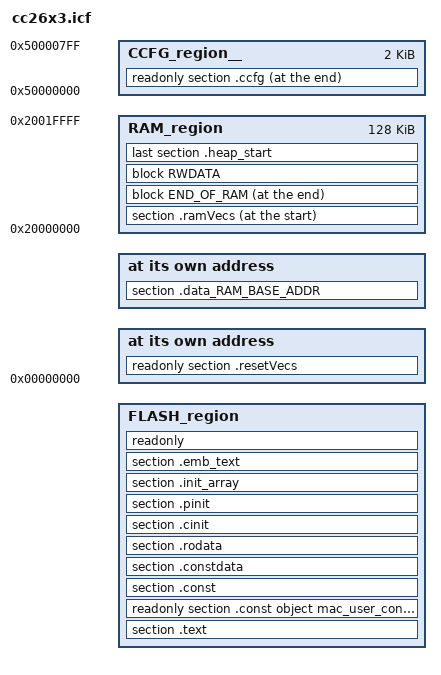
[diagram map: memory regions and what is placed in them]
/******************************************************************************

 @file  cc26x3.icf

 @brief Linker configuration file for sensor/collector on cc13x2/cc26x2 devices

 Group: WCS LPC
 Target Device: cc13xx_cc26xx

 ******************************************************************************
 
 Copyright (c) 2016-2025, Texas Instruments Incorporated
 All rights reserved.

 Redistribution and use in source and binary forms, with or without
 modification, are permitted provided that the following conditions
 are met:

 *  Redistributions of source code must retain the above copyright
    notice, this list of conditions and the following disclaimer.

 *  Redistributions in binary form must reproduce the above copyright
    notice, this list of conditions and the following disclaimer in the
    documentation and/or other materials provided with the distribution.

 *  Neither the name of Texas Instruments Incorporated nor the names of
    its contributors may be used to endorse or promote products derived
    from this software without specific prior written permission.

 THIS SOFTWARE IS PROVIDED BY THE COPYRIGHT HOLDERS AND CONTRIBUTORS "AS IS"
 AND ANY EXPRESS OR IMPLIED WARRANTIES, INCLUDING, BUT NOT LIMITED TO,
 THE IMPLIED WARRANTIES OF MERCHANTABILITY AND FITNESS FOR A PARTICULAR
 PURPOSE ARE DISCLAIMED. IN NO EVENT SHALL THE COPYRIGHT OWNER OR
 CONTRIBUTORS BE LIABLE FOR ANY DIRECT, INDIRECT, INCIDENTAL, SPECIAL,
 EXEMPLARY, OR CONSEQUENTIAL DAMAGES (INCLUDING, BUT NOT LIMITED TO,
 PROCUREMENT OF SUBSTITUTE GOODS OR SERVICES; LOSS OF USE, DATA, OR PROFITS;
 OR BUSINESS INTERRUPTION) HOWEVER CAUSED AND ON ANY THEORY OF LIABILITY,
 WHETHER IN CONTRACT, STRICT LIABILITY, OR TORT (INCLUDING NEGLIGENCE OR
 OTHERWISE) ARISING IN ANY WAY OUT OF THE USE OF THIS SOFTWARE,
 EVEN IF ADVISED OF THE POSSIBILITY OF SUCH DAMAGE.

 ******************************************************************************
 
 
 *****************************************************************************/

///////////////////////////////////////////////////////////////////////////////
// Memory Sizes
///////////////////////////////////////////////////////////////////////////////

/* Intvec start */
define symbol FLASH_BASE__         = 0x00000000;
define symbol CCFG_base__          = 0x50000000;
define symbol RAM_base__           = 0x20000000;

define symbol FLASH_SIZE__         = 0x100000;
define symbol CCFG_size__          = 0x800;
define symbol RAM_size__           = 0x20000;

///////////////////////////////////////////////////////////////////////////////
// Memory Definitions
///////////////////////////////////////////////////////////////////////////////

///////////////////////////////////////////////////////////////////////////////
// Flash
//
define symbol WORD_SIZE            = 4;
define symbol FLASH_MEM_ALIGN      = WORD_SIZE;

/* Define a memory region that covers the entire 4 GB addressable space */
define memory mem with size = 4G;

/* Memory Regions */
/* Define a region for the on-chip flash
 * Note there are some holes in this memory due to issues with
 * first-sampling silicon.
 */
define region FLASH_region = [from 0x0 to 0x1BFFF] | [from 0x24000 to 0x5BFFF] | [from 0x64000 to 0x9BFFF] | [from 0xA4000 to 0xDBFFF] | [from 0xE4000 to 0xFFFFF];

/* Define a region for the last flash page */
define region CCFG_region__ = mem:[from CCFG_base__ size CCFG_size__];

///////////////////////////////////////////////////////////////////////////////
// RAM
//

/* Internal RAM for data used by application */
define region RAM_region = mem:[from RAM_base__ size RAM_size__];

///////////////////////////////////////////////////////////////////////////////
// Memory Placement
///////////////////////////////////////////////////////////////////////////////

///////////////////////////////////////////////////////////////////////////////
// Memory Placement in Flash
//

/* Place the interrupt vectors at the start of flash */
place at address mem:FLASH_BASE__ { readonly section .resetVecs };
keep { section .resetVecs};

/* Place the CCA area at the end of flash */
place at end of CCFG_region__ { readonly section .ccfg };
keep { section .ccfg };

// place in CCFG_region__ { section .text object macTask.o };
// place in CCFG_region__ { section .text object api_mac.o };
// place in CCFG_region__ { section .text object osal_port.o };
// place in CCFG_region__ { section .text object saddr.o };

place in FLASH_region { section .text };

place in FLASH_region { readonly section .const object mac_user_config.o };

place in FLASH_region { 
	section .const,
	section .constdata,
	section .rodata,
	section .cinit,
	section .pinit,
	section .init_array,
	section .emb_text
};

/* Place remaining 'read only' in Flash */
place in FLASH_region { readonly };

///////////////////////////////////////////////////////////////////////////////
// Memory Placement in RAM
//

/* Place .ramVecs in start of RAM */
place at start of RAM_region { section .ramVecs };
/*
place in RAM_region  {
	section .data,
	section .bss,
	section .ramVecs,
	section .sysmem,
	section .nonretenvar,
};
*/

/*
 * Define CSTACK block to contain .stack section. This enables the IAR IDE
 * to properly show the stack content during debug. Place stack at end of
 * retention RAM, do not initialize (initializing the stack will destroy the
 * return address from the initialization code, causing the processor to branch
 * to zero and fault)
 */
define symbol STACKSIZE = 1024;
define block CSTACK with alignment = 8, size = STACKSIZE { section .stack };

//place at end of RAM_region { block CSTACK };
if (isdefinedsymbol(ROM_TIMACDataAddr)) {
    place at address mem:ROM_TIMACDataAddr {section .data_RAM_BASE_ADDR };
}

/* Export stack top symbol. Used by startup file */
define exported symbol STACK_TOP = end(RAM_region) + 1;

define block RWDATA { rw };

define section .heap_start            { public heapStart: };
define section .heap_end              { public heapEnd: };
define block   HEAP_END with size = 1 { section .heap_end };

define block END_OF_RAM with fixed order {
                                        block HEAP_END,
                                        block CSTACK
                                      };
place at end of RAM_region { block END_OF_RAM };

place in RAM_region { block RWDATA,
               last section .heap_start};


initialize by copy { readwrite };
do not initialize { section .stack, section .noinit};

///////////////////////////////////////////////////////////////////////////////
// Other Linker Directives
///////////////////////////////////////////////////////////////////////////////

/*
 * The USE_TIRTOS_ROM symbol is defined internally in the build flow (using
 * --config_def USE_TIRTOS_ROM=1) for TI-RTOS applications whose app.cfg file
 * specifies to use the ROM.
 */
if (isdefinedsymbol(USE_TIRTOS_ROM)) {
    include "TIRTOS_ROM.icf";
}
